# M3351 register map
File version: 1.0
Registers are 32-bit, read-write, reset 0x0 unless marked. A register's access mark holds for its fields unless they carry their own. Offsets are from the block's base; [hi:lo] are bit positions; {n}, {i} and the like mark numbered series; 'fields as' and 'values as' point back to an identical list.

## ACMP01 — ACMP Register Map
Base 0x40045000
Same registers: ACMP01_NS 0x50045000
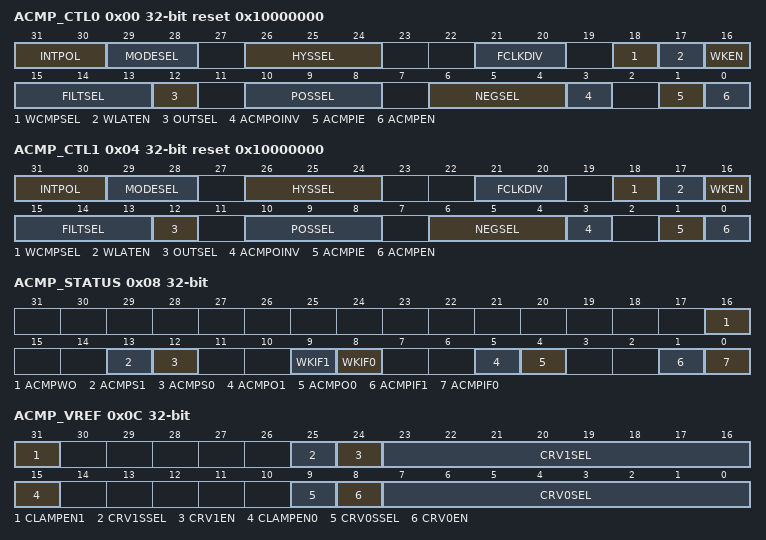
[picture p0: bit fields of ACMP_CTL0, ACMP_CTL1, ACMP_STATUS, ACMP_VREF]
0x00 ACMP_CTL0 reset 0x10000000 — Analog Comparator Control Register 0
  [31:30] INTPOL — Interrupt Condition Polarity Selection. ACMPIF0 will be set to 1 when ACMP output edge condition is detected.
    0=Rising edge or falling edge; 1=Rising edge; 2=Falling edge
  [29:28] MODESEL — ACMP Operating Mode Selection. The register affects analog characteristics as operating current, input offset voltage, setup time, propagation delay, etc. Note: Please refer to Analog comparator (ACMP) of Analog characteristics in the Datasheet.
    {v}=ACMP0 operating mode{v} (v=0..3)
  [26:24] HYSSEL — Hysteresis Mode Selection
    0=Hysteresis is 0mV; 1=Hysteresis is 10mV; 2=Hysteresis is 20mV; 3=Hysteresis is 30mV; 4=Hysteresis is 40mV
  [21:20] FCLKDIV — ACMP Output Filter Clock Divider
    0=ACMP0 output filter clock = PCLK; 1=ACMP0 output filter clock = PCLK/2; 2=ACMP0 output filter clock = PCLK/4
  [18] WCMPSEL — Window Compare Mode Selection
    0=Window Compare Mode Disabled; 1=Window Compare Mode Selected
  [17] WLATEN — Window Latch Mode Enable Bit
    0=Window Latch Mode Disabled; 1=Window Latch Mode Enabled
  [16] WKEN — Power-down Wake-up Enable Bit
    0=Wake-up function Disabled; 1=Wake-up function Enabled
  [15:13] FILTSEL — ACMP Output Filter Count Selection
    0=Filter function is Disabled; 1=ACMP0 output is sampled 1 consecutive PCLK; 2=ACMP0 output is sampled 2 consecutive PCLKs; 3=ACMP0 output is sampled 4 consecutive PCLKs; 4=ACMP0 output is sampled 8 consecutive PCLKs; 5=ACMP0 output is sampled 16 consecutive PCLKs; 6=ACMP0 output is sampled 32 consecutive PCLKs; 7=ACMP0 output is sampled 64 consecutive PCLKs
  [12] OUTSEL — ACMP Output Select
    0=ACMP0 output to ACMP0_O pin is unfiltered ACMP output; 1=ACMP0 output to ACMP0_O pin is from filter output
  [10:8] POSSEL — ACMP Positive Input Selection
    {v}=ACMP0_P{v} pin (v=0..3)
  [6:4] NEGSEL — ACMP Negative Input Selection. Note: NEGSEL must select 0x1 in calibration mode.
    0=ACMP0_N; 1=Internal comparator reference voltage (CRV0); 2=Band-gap voltage; 3=DAC0
  [3] ACMPOINV — ACMP Output Inverse
    0=ACMP0 output inverse Disabled; 1=ACMP0 output inverse Enabled
  [1] ACMPIE — ACMP Interrupt Enable Bit. Note:If WKEN (ACMP_CTL0[16]) is set to 1, the wake-up interrupt function will be enabled as well.
    0=ACMP0 interrupt Disabled; 1=ACMP0 interrupt Enabled
  [0] ACMPEN — ACMP Enable Bit
    0=ACMP 0 Disabled; 1=ACMP 0 Enabled
0x04 ACMP_CTL1 reset 0x10000000 — Analog Comparator Control Register 1
  [31:30] INTPOL — Interrupt Condition Polarity Selection. ACMPIF1 will be set to 1 when ACMP output edge condition is detected.
    0=Rising edge or falling edge; 1=Rising edge; 2=Falling edge
  [29:28] MODESEL — ACMP Operating Mode Selection. The register affects analog characteristics as operating current, input offset voltage, setup time, propagation delay, etc. Note: Please refer to Analog comparator (ACMP) of Analog characteristics in the Datasheet.
    {v}=ACMP1 operating mode{v} (v=0..3)
  [26:24] HYSSEL — Hysteresis Mode Selection
    values as ACMP_CTL0.HYSSEL
  [21:20] FCLKDIV — ACMP Output Filter Clock Divider
    0=ACMP1 output filter clock = PCLK; 1=ACMP1 output filter clock = PCLK/2; 2=ACMP1 output filter clock = PCLK/4
  [18] WCMPSEL — Window Compare Mode Selection
    0=Window Compare Mode Disabled; 1=Window Compare Mode is Selected
  [17] WLATEN — Window Latch Mode Enable Bit
    0=Window Latch Mode Disabled; 1=Window Latch Mode Enabled
  [16] WKEN — Power-down Wake-up Enable Bit
    0=Wake-up function Disabled; 1=Wake-up function Enabled
  [15:13] FILTSEL — ACMP Output Filter Count Selection
    0=Filter function is Disabled; 1=ACMP1 output is sampled 1 consecutive PCLK; 2=ACMP1 output is sampled 2 consecutive PCLKs; 3=ACMP1 output is sampled 4 consecutive PCLKs; 4=ACMP1 output is sampled 8 consecutive PCLKs; 5=ACMP1 output is sampled 16 consecutive PCLKs; 6=ACMP1 output is sampled 32 consecutive PCLKs; 7=ACMP1 output is sampled 64 consecutive PCLKs
  [12] OUTSEL — ACMP Output Selection
    0=ACMP1 output to ACMP1_O pin is unfiltered ACMP output; 1=ACMP1 output to ACMP1_O pin is from filter output
  [10:8] POSSEL — ACMP Positive Input Selection
    {v}=ACMP1_P{v} pin (v=0..3)
  [6:4] NEGSEL — ACMP Negative Input Selection. Note: NEGSEL must select 0x1 in calibration mode.
    0=ACMP1_N; 1=Internal comparator reference voltage (CRV1); 2=Band-gap voltage; 3=DAC0
  [3] ACMPOINV — ACMP Output Inverse
    0=ACMP1 output inverse Disabled; 1=ACMP1 output inverse Enabled
  [1] ACMPIE — ACMP Interrupt Enable Bit. Note:If WKEN (ACMP_CTL1[16]) is set to 1, the wake-up interrupt function will be enabled as well.
    0=ACMP1 interrupt Disabled; 1=ACMP1 interrupt Enabled
  [0] ACMPEN — ACMP Enable Bit
    0=ACMP1 Disabled; 1=ACMP1 Enabled
0x08 ACMP_STATUS — Analog Comparator Status Register
  [16] ACMPWO — ACMP Window Output. This bit shows the output status of window compare mode
    0=The positive input voltage is outside the window; 1=The positive input voltage is in the window
  [13] ACMPS1 — ACMP Status 1. Synchronized to the PCLK to allow reading by software. Cleared when the ACMP1 is disabled, i.e. ACMPEN (ACMP_CTL1[0]) is cleared to 0.
  [12] ACMPS0 — ACMP Status 0. Synchronized to the PCLK to allow reading by software. Cleared when the ACMP 0 is disabled, i.e. ACMPEN (ACMP_CTL0[0]) is cleared to 0.
  [9] WKIF1 — ACMP Power-down Wake-up Interrupt Flag 1. This bit will be set to 1 when ACMP1 wake-up interrupt event occurs. Note: Write 1 to clear this bit to 0.
    0=No power-down wake-up occurred; 1=Power-down wake-up occurred
  [8] WKIF0 — ACMP Power-down Wake-up Interrupt Flag 0. This bit will be set to 1 when ACMP0 wake-up interrupt event occurs. Note: Write 1 to clear this bit to 0.
    values as WKIF1
  [5] ACMPO1 — ACMP Output 1. Synchronized to the PCLK to allow reading by software. Cleared when the ACMP1 is disabled, i.e. ACMPEN (ACMP_CTL1[0]) is cleared to 0.
  [4] ACMPO0 — ACMP Output 0. Synchronized to the PCLK to allow reading by software. Cleared when the ACMP0 is disabled, i.e. ACMPEN (ACMP_CTL0[0]) is cleared to 0.
  [1] ACMPIF1 — ACMP Interrupt Flag 1. This bit is set by hardware when the edge condition defined by INTPOL (ACMP_CTL1[31:30]) is detected on ACMP1 output. This will cause an interrupt if ACMPIE (ACMP_CTL1[1]) is set to 1. Note: Write 1 to clear this bit to 0.
  [0] ACMPIF0 — ACMP Interrupt Flag 0. This bit is set by hardware when the edge condition defined by INTPOL (ACMP_CTL0[31:30]) is detected on ACMP0 output. This will generate an interrupt if ACMPIE (ACMP_CTL0[1]) is set to 1. Note: Write 1 to clear this bit to 0.
0x0C ACMP_VREF — Analog Comparator Reference Voltage Control Register
  [31] CLAMPEN1 — ACMP Speed Up Function Enable Bit
    0=ACMP1 Speed Up Function Disabled; 1=ACMP1 Speed Up Function Enabled
  [25] CRV1SSEL — CRV1 Source Voltage Selection
    0=AVDD is selected as CRV1 source voltage; 1=The reference voltage defined by VREFCTL (SYS_VREFCTL[4:0]) register is selected as CRV1 source voltage
  [24] CRV1EN — CRV1 Enable Bit
    0=CRV1 Disabled; 1=CRV1 Enabled
  [23:16] CRV1SEL — ACMP Reference Voltage Setting 1. Set CRV output voltage for ACMP1 negtive input.
  [15] CLAMPEN0 — ACMP Speed Up Function Enable Bit
    0=ACMP0 Speed Up Function Disabled; 1=ACMP0 Speed Up Function Enabled
  [9] CRV0SSEL — CRV0 Source Voltage Selection
    0=AVDD is selected as CRV0 source voltage; 1=The reference voltage defined by VREFCTL (SYS_VREFCTL[4:0]) register is selected as CRV0 source voltage
  [8] CRV0EN — CRV0 Enable Bit
    0=CRV0 Disabled; 1=CRV0 Enabled
  [7:0] CRV0SEL — ACMP Reference Voltage Setting 0. Set CRV output voltage for ACMP0 negtive input.
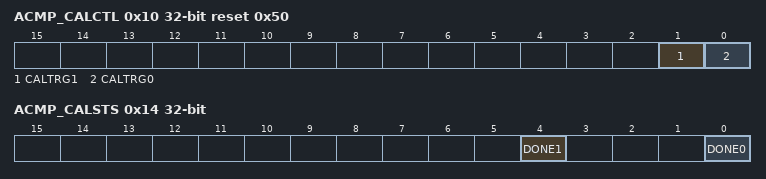
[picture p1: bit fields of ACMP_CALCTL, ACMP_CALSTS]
0x10 ACMP_CALCTL reset 0x50 — Analog Comparator Calibration Control Register
  [1] CALTRG1 — ACMP Calibration Trigger 1. Set ACMP1 calibration trigger. Note 1: Before this bit is enabled, ACMPEN(ACMP_CTL1[0]) should be set and the internal high speed RC oscillator (HIRC) should be enabled in advance. Note 2: Hardware will automatically clear this bit when the next calibration is triggered by software. Note 3: If user must trigger calibration twice or more times, the second trigger has to wait at least 300us after the previous calibration is done.
    0=Calibration is stopped; 1=Calibration is triggered
  [0] CALTRG0 — ACMP Calibration Trigger 0. Set ACMP0 calibration trigger. Note 1: Before this bit is enabled, ACMPEN(ACMP_CTL0[0]) should be set and the internal high speed RC oscillator (HIRC) should be enabled in advance. Note 2: Hardware will automatically clear this bit when the next calibration is triggered by software. Note 3: If user must trigger calibration twice or more times, the second trigger has to wait at least 300us after the previous calibration is done.
    0=Calibration is stopped; 1=Calibration is triggered
0x14 ACMP_CALSTS — Analog Comparator Calibration Status Register
  [4] DONE1 — ACMP Calibration Done Status 1. This bit will be set when ACMP1 calibration is done. Note: Write 1 to clear this bit to 0.
    0=Calibrating; 1=Calibration done
  [0] DONE0 — ACMP Calibration Done Status 0. This bit will be set when ACMP0 calibration is done. Note: Write 1 to clear this bit to 0.
    0=Calibrating; 1=Calibration done
